AUTOSAR XML (schema 4-1-3)
standard types defined: boolean, sint8, uint16, uint32, uint8, boolean_CompuMethod, boolean_DataConstr, sint8_DataConstr, uint16_DataConstr, uint32_DataConstr, uint8_DataConstr, sint16
package /MICROSAR/Dem_swc/DataTypes
  5 x impl type:
    Dem_DebounceResetStatusType: compu {0=DEM_DEBOUNCE_STATUS_FREEZE, 1=DEM_DEBOUNCE_STATUS_RESET}, range raw 0..255, implementation-data-type=ImplementationDataTypes/uint8
    Dem_DTCFormatType: compu {0=DEM_DTC_FORMAT_OBD, 1=DEM_DTC_FORMAT_UDS, 2=DEM_DTC_FORMAT_J1939}, range raw 0..2, implementation-data-type=ImplementationDataTypes/uint8
    Dem_EventStatusType:
      compu {0=DEM_EVENT_STATUS_PASSED, 1=DEM_EVENT_STATUS_FAILED, 2=DEM_EVENT_STATUS_PREPASSED, 3=DEM_EVENT_STATUS_PREFAILED, 4=DEM_EVENT_STATUS_FDC_THRESHOLD_REACHED, 5=DEM_EVENT_STATUS_PASSED_CONDITIONS_NOT_FULFILLED, 6=DEM_EVENT_STATUS_FAILED_CONDITIONS_NOT_FULFILLED, 7=DEM_EVENT_STATUS_PREPASSED_CONDITIONS_NOT_FULFILLED, 8=DEM_EVENT_STATUS_PREFAILED_CONDITIONS_NOT_FULFILLED}
      range raw 0..255
      implementation-data-type=ImplementationDataTypes/uint8
    Dem_MaxDataValueType: category=ARRAY, sw-calibration-access=READ-ONLY
      element Dem_MaxDataValueTypeElement: array-size=14, array-size-semantics=FIXED-SIZE, implementation-data-type=ImplementationDataTypes/uint8
    Dem_UdsStatusByteType:
      compu {mask 1: 1=DEM_UDS_STATUS_TF (bit 0: TestFailed), mask 2: 2=DEM_UDS_STATUS_TFTOC (bit 1: TestFailedThisOperationCycle), mask 4: 4=DEM_UDS_STATUS_PDTC (bit 2: PendingDTC), mask 8: 8=DEM_UDS_STATUS_CDTC (bit 3: ConfirmedDTC), mask 16: 16=DEM_UDS_STATUS_TNCSLC (bit 4: TestNotCompletedSinceLastClear), mask 32: 32=DEM_UDS_STATUS_TFSLC (bit 5: TestFailedSinceLastClear), mask 64: 64=DEM_UDS_STATUS_TNCTOC (bit 6: TestNotCompletedThisOperationCycle), mask 128: 128=DEM_UDS_STATUS_WIR (bit 7: WarningIndicatorRequested)}
      range raw 0..255
      implementation-data-type=ImplementationDataTypes/uint8
package /MICROSAR/Dem_swc/Interfaces
  client server interface DiagnosticMonitor: is-service=true, service-kind=DIAGNOSTIC-EVENT-MANAGER
    11 x operation:
      GetDTCOfEvent: possible-error=[DEM_E_NO_DTC_AVAILABLE, E_NOT_OK]
        arg DTCFormat: type=Dem_DTCFormatType, direction=IN, server-argument-impl-policy=USE-ARGUMENT-TYPE
        arg DTCOfEvent: type=ImplementationDataTypes/uint32, direction=OUT, server-argument-impl-policy=USE-ARGUMENT-TYPE
      GetEventExtendedDataRecordEx: possible-error=[DEM_BUFFER_TOO_SMALL, DEM_NO_SUCH_ELEMENT, E_NOT_OK]
        arg RecordNumber: type=ImplementationDataTypes/uint8, direction=IN, server-argument-impl-policy=USE-ARGUMENT-TYPE
        arg DestBuffer: type=Dem_MaxDataValueType, direction=OUT, server-argument-impl-policy=USE-ARGUMENT-TYPE
        arg BufSize: type=ImplementationDataTypes/uint16, direction=INOUT, server-argument-impl-policy=USE-ARGUMENT-TYPE
      GetEventFailed: possible-error=E_NOT_OK
        arg EventFailed: type=ImplementationDataTypes/boolean, direction=OUT, server-argument-impl-policy=USE-ARGUMENT-TYPE
      GetEventFreezeFrameDataEx: possible-error=[DEM_BUFFER_TOO_SMALL, DEM_NO_SUCH_ELEMENT, E_NOT_OK]
        4 x arg, all with server-argument-impl-policy=USE-ARGUMENT-TYPE:
          RecordNumber: type=ImplementationDataTypes/uint8, direction=IN
          DataId: type=ImplementationDataTypes/uint16, direction=IN
          DestBuffer: type=Dem_MaxDataValueType, direction=OUT
          BufSize: type=ImplementationDataTypes/uint16, direction=INOUT
      GetEventStatus: possible-error=E_NOT_OK
        arg UDSStatusByte: type=Dem_UdsStatusByteType, direction=OUT, server-argument-impl-policy=USE-ARGUMENT-TYPE
      GetEventTested: possible-error=E_NOT_OK
        arg EventTested: type=ImplementationDataTypes/boolean, direction=OUT, server-argument-impl-policy=USE-ARGUMENT-TYPE
      GetEventUdsStatus: possible-error=E_NOT_OK
        arg UDSStatusByte: type=Dem_UdsStatusByteType, direction=OUT, server-argument-impl-policy=USE-ARGUMENT-TYPE
      GetFaultDetectionCounter: possible-error=[DEM_E_NO_FDC_AVAILABLE, E_NOT_OK]
        arg FaultDetectionCounter: type=sint8, direction=OUT, server-argument-impl-policy=USE-ARGUMENT-TYPE
      ResetEventDebounceStatus: possible-error=E_NOT_OK
        arg DebounceResetStatus: type=Dem_DebounceResetStatusType, direction=IN, server-argument-impl-policy=USE-ARGUMENT-TYPE
      ResetEventStatus: possible-error=E_NOT_OK
      SetEventStatus: possible-error=E_NOT_OK
        arg EventStatus: type=Dem_EventStatusType, direction=IN, server-argument-impl-policy=USE-ARGUMENT-TYPE
    5 x error:
      DEM_BUFFER_TOO_SMALL: error-code=21
      DEM_E_NO_DTC_AVAILABLE: error-code=10
      DEM_E_NO_FDC_AVAILABLE: error-code=14
      DEM_NO_SUCH_ELEMENT: error-code=48
      E_NOT_OK: error-code=1
package /RB/ApplicationSW/PT/CompuMethods
  compu method CM_boolean: 0=FALSE, 1=TRUE
package /RB/ApplicationSW/PT/Units
  unit NoUnit: factor-si-to-unit=1, offset-si-to-unit=0
package /UAES/ASW/ApplicationDataType
  application array data type Array_Curr_q0p01_A_s16_10: category=ARRAY, sw-calibration-access=READ-WRITE
    element Array_Curr_q0p01_A_s16_10: category=VALUE, type=ApplicationDataType/Curr_q0p01_A_s16, array-size-semantics=FIXED-SIZE, max-number-of-elements=10
  app type Curr_q0p01_A_s16: category=VALUE, sw-calibration-access=READ-WRITE, compu {phys=raw*0.01 for raw -INF..INF; unit A}, range raw -32768..32767
package /UAES/ASW/ApplicationDataTypes
  application array data type Array_Curr_q0p01_A_s16_10: category=ARRAY, sw-calibration-access=READ-WRITE
    element Array_Curr_q0p01_A_s16_10: category=VALUE, type=ApplicationDataTypes/Curr_q0p01_A_s16, array-size-semantics=FIXED-SIZE, max-number-of-elements=10
  4 x app type, all with category=VALUE, sw-calibration-access=READ-WRITE:
    Curr_q0p01_A_s16: compu {phys=raw*0.01 for raw -INF..INF; unit A}, range phys -327.68..-327.67
    Curr_q0p136_A_s16: compu {phys=raw*0.136 for raw -INF..INF; unit A}, range phys -100..100
    T_q1_o63_DegC_s16: compu {phys=raw-63 for raw -INF..INF; unit ℃}, range phys -63..650
    Tq_q0p001_kN_u16: compu {phys=raw*0.001 for raw -INF..INF; unit kN}, range phys 0..50
package /UAES/ASW/DataConstrs
  range DC_boolean: raw 0..1
  range DC_sint16: raw -32768..32767
  range DC_uint16: raw 0..65535
  range DC_uint32: raw 0..4294967295
  range DC_uint8: raw 0..255
package /UAES/ASW/DataTypeMappingSets
  data type mapping set DTMS_EPB_SysSrvAdpCust
    data-type-maps:
      application-data-type=ApplicationDataType/Array_Curr_q0p01_A_s16_10, implementation-data-type=Array_sint16_10
      application-data-type=ApplicationDataType/Curr_q0p01_A_s16, implementation-data-type=sint16
      application-data-type=ApplicationDataTypes/Array_Curr_q0p01_A_s16_10, implementation-data-type=Array_sint16_10
      application-data-type=ApplicationDataTypes/Curr_q0p01_A_s16, implementation-data-type=sint16
      application-data-type=Curr_q0p136_A_s16, implementation-data-type=sint16
      application-data-type=T_q1_o63_DegC_s16, implementation-data-type=sint16
      application-data-type=Tq_q0p001_kN_u16, implementation-data-type=ImplementationDataTypes/uint16
package /UAES/ASW/ImplementationDataTypes
  6 x impl type, all with category=ARRAY, sw-calibration-access=READ-ONLY, type-emitter=RTE:
    Array_sint16_10
      element Array_sint16_10: array-size=10, array-size-semantics=FIXED-SIZE, implementation-data-type=sint16
    Array_uint8_128
      element Array_uint8_128: array-size=128, array-size-semantics=FIXED-SIZE, implementation-data-type=ImplementationDataTypes/uint8
    Array_uint8_30
      element Array_uint8_30: array-size=30, array-size-semantics=FIXED-SIZE, implementation-data-type=ImplementationDataTypes/uint8
    Array_uint8_4
      element Array_uint8_4: array-size=4, array-size-semantics=FIXED-SIZE, implementation-data-type=ImplementationDataTypes/uint8
    Array_uint8_40
      element Array_uint8_40: array-size=40, array-size-semantics=FIXED-SIZE, implementation-data-type=ImplementationDataTypes/uint8
    Array_uint8_6
      element Array_uint8_6: array-size=6, array-size-semantics=FIXED-SIZE, implementation-data-type=ImplementationDataTypes/uint8
package /UAES/ASW/PortInterfaces
  43 x sender receiver interface:
    EPB_bFunctionFailed: invalidation-policy{data-element=EPB_bFunctionFailed/Val, handle-invalid=DONT-INVALIDATE}
      data Val: sw-calibration-access=READ-ONLY, type=ImplementationDataTypes/boolean
    EPB_cntPbcOutDiagActuationCounter: invalidation-policy{data-element=EPB_cntPbcOutDiagActuationCounter/Val, handle-invalid=DONT-INVALIDATE}
      data Val: sw-calibration-access=READ-ONLY, type=ImplementationDataTypes/uint32
    EPB_PbcInHostSwVersion: invalidation-policy{data-element=EPB_PbcInHostSwVersion/Val, handle-invalid=DONT-INVALIDATE}
      data Val: sw-calibration-access=READ-ONLY, type=Array_uint8_6
    EPB_PbcOutPbcSoftwareVersion: invalidation-policy{data-element=EPB_PbcOutPbcSoftwareVersion/Val, handle-invalid=DONT-INVALIDATE}
      data Val: sw-calibration-access=READ-ONLY, type=Array_uint8_6
    EPB_SSMInDataStorageRead: invalidation-policy{data-element=EPB_SSMInDataStorageRead/Val, handle-invalid=DONT-INVALIDATE}
      data Val: sw-calibration-access=READ-WRITE, type=Array_uint8_128
    EPB_SSMOutDataStorageWrite: invalidation-policy{data-element=EPB_SSMOutDataStorageWrite/Val, handle-invalid=DONT-INVALIDATE}
      data Val: sw-calibration-access=READ-WRITE, type=Array_uint8_128
    EPB_stButtonInFaultMonitorStatusReset: invalidation-policy{data-element=EPB_stButtonInFaultMonitorStatusReset/Val, handle-invalid=DONT-INVALIDATE}
      data Val: sw-calibration-access=READ-WRITE, type=ImplementationDataTypes/uint8
    EPB_stButtonOutFaultMonitorStatus: invalidation-policy{data-element=EPB_stButtonOutFaultMonitorStatus/Val, handle-invalid=DONT-INVALIDATE}
      data Val: sw-calibration-access=READ-WRITE, type=ImplementationDataTypes/uint8
    EPB_stPbcOutDiagActuatorState: invalidation-policy{data-element=EPB_stPbcOutDiagActuatorState/Val, handle-invalid=DONT-INVALIDATE}
      data Val: sw-calibration-access=READ-ONLY, type=ImplementationDataTypes/uint8
    EPB_stPbcOutEcuPowerLatchRequest: invalidation-policy{data-element=EPB_stPbcOutEcuPowerLatchRequest/Val, handle-invalid=DONT-INVALIDATE}
      data Val: sw-calibration-access=READ-ONLY, type=ImplementationDataTypes/uint8
    EPB_stPbcOutFaultStatus: invalidation-policy{data-element=EPB_stPbcOutFaultStatus/Val, handle-invalid=DONT-INVALIDATE}
      data Val: sw-calibration-access=READ-WRITE, type=Array_uint8_40
    EPB_stSSMInDataStorageValid: invalidation-policy{data-element=EPB_stSSMInDataStorageValid/Val, handle-invalid=DONT-INVALIDATE}
      data Val: sw-calibration-access=READ-WRITE, type=ImplementationDataTypes/uint8
    EPB_stSsmInFunctionConfig: invalidation-policy{data-element=EPB_stSsmInFunctionConfig/Val, handle-invalid=DONT-INVALIDATE}
      data Val: sw-calibration-access=READ-ONLY, type=ImplementationDataTypes/uint8
    EPB_stSsmInVariantCode: invalidation-policy{data-element=EPB_stSsmInVariantCode/Val, handle-invalid=DONT-INVALIDATE}
      data Val: sw-calibration-access=READ-ONLY, type=Array_uint8_4
    EPB_stSsmInVehicleTypeCfg: invalidation-policy{data-element=EPB_stSsmInVehicleTypeCfg/Val, handle-invalid=DONT-INVALIDATE}
      data Val: sw-calibration-access=READ-ONLY, type=ImplementationDataTypes/uint8
    EPB_stSsmOutCommunicationLatchRequest: invalidation-policy{data-element=EPB_stSsmOutCommunicationLatchRequest/Val, handle-invalid=DONT-INVALIDATE}
      data Val: sw-calibration-access=READ-ONLY, type=ImplementationDataTypes/uint8
    EPB_stSsmOutEpbSwtCycle: invalidation-policy{data-element=EPB_stSsmOutEpbSwtCycle/Val, handle-invalid=DONT-INVALIDATE}
      data Val: sw-calibration-access=READ-ONLY, type=ImplementationDataTypes/uint8
    EPB_stSsmOutFaultStatus: invalidation-policy{data-element=EPB_stSsmOutFaultStatus/Val, handle-invalid=DONT-INVALIDATE}
      data Val: sw-calibration-access=READ-ONLY, type=Array_uint8_30
    EPB_stSsmOutPrkBrkAplSwt: invalidation-policy{data-element=EPB_stSsmOutPrkBrkAplSwt/Val, handle-invalid=DONT-INVALIDATE}
      data Val: sw-calibration-access=READ-ONLY, type=ImplementationDataTypes/uint8
    EPB_stSsmOutSysState: invalidation-policy{data-element=EPB_stSsmOutSysState/Val, handle-invalid=DONT-INVALIDATE}
      data Val: sw-calibration-access=READ-ONLY, type=ImplementationDataTypes/uint8
    EPB_tPbcOutDiagBrakeTemperature: invalidation-policy{data-element=EPB_tPbcOutDiagBrakeTemperature/Val, handle-invalid=DONT-INVALIDATE}
      data Val: sw-calibration-access=READ-ONLY, type=sint16
    EPB_tqPbcOutDiagAchievedClampForce: invalidation-policy{data-element=EPB_tqPbcOutDiagAchievedClampForce/Val, handle-invalid=DONT-INVALIDATE}
      data Val: sw-calibration-access=READ-ONLY, type=ImplementationDataTypes/uint16
    EPBCalprDrvr_CurrMotDrvrCurr_a: invalidation-policy{data-element=EPBCalprDrvr_CurrMotDrvrCurr_a/Val, handle-invalid=DONT-INVALIDATE}
      data Val: sw-calibration-access=READ-ONLY, type=ApplicationDataType/Array_Curr_q0p01_A_s16_10
    gCFG_u8SsmInFunctionConfig: invalidation-policy{data-element=gCFG_u8SsmInFunctionConfig/Val, handle-invalid=DONT-INVALIDATE}
      data Val: sw-calibration-access=READ-ONLY, type=ImplementationDataTypes/uint8
    gCFG_u8SsmInVariantCoding: invalidation-policy{data-element=gCFG_u8SsmInVariantCoding/Val, handle-invalid=DONT-INVALIDATE}
      data Val: sw-calibration-access=READ-ONLY, type=Array_uint8_4
    gDiag_bDSMClear: invalidation-policy{data-element=gDiag_bDSMClear/Val, handle-invalid=DONT-INVALIDATE}
      data Val: sw-calibration-access=READ-ONLY, type=ImplementationDataTypes/boolean
    gEPB_s16PbcOutCurrMotDrvrCurr: invalidation-policy{data-element=gEPB_s16PbcOutCurrMotDrvrCurr/Val, handle-invalid=DONT-INVALIDATE}
      data Val: sw-calibration-access=READ-ONLY, type=Curr_q0p136_A_s16
    gEPB_s16PbcOutDiagBrakeTemperature: invalidation-policy{data-element=gEPB_s16PbcOutDiagBrakeTemperature/Val, handle-invalid=DONT-INVALIDATE}
      data Val: sw-calibration-access=READ-ONLY, type=T_q1_o63_DegC_s16
    gEPB_u16PbcOutDiagAchievedClampForce: invalidation-policy{data-element=gEPB_u16PbcOutDiagAchievedClampForce/Val, handle-invalid=DONT-INVALIDATE}
      data Val: sw-calibration-access=READ-ONLY, type=Tq_q0p001_kN_u16
    gEPB_u32AllowSleep_Local: invalidation-policy{data-element=gEPB_u32AllowSleep_Local/Val, handle-invalid=DONT-INVALIDATE}
      data Val: sw-calibration-access=READ-ONLY, type=ImplementationDataTypes/uint32
    gEPB_u32AllowSleep_NW: invalidation-policy{data-element=gEPB_u32AllowSleep_NW/Val, handle-invalid=DONT-INVALIDATE}
      data Val: sw-calibration-access=READ-ONLY, type=ImplementationDataTypes/uint32
    gEPB_u32PbcOutDiagActuationCounter: invalidation-policy{data-element=gEPB_u32PbcOutDiagActuationCounter/Val, handle-invalid=DONT-INVALIDATE}
      data Val: sw-calibration-access=READ-ONLY, type=ImplementationDataTypes/uint32
    gEPB_u8HostSoftwareVersion: invalidation-policy{data-element=gEPB_u8HostSoftwareVersion/Val, handle-invalid=DONT-INVALIDATE}
      data Val: sw-calibration-access=READ-ONLY, type=Array_uint8_6
    gEPB_u8PbcOutDiagActuatorState: invalidation-policy{data-element=gEPB_u8PbcOutDiagActuatorState/Val, handle-invalid=DONT-INVALIDATE}
      data Val: sw-calibration-access=READ-ONLY, type=ImplementationDataTypes/uint8
    gEPB_u8PbcOutPbcSoftwareVersion: invalidation-policy{data-element=gEPB_u8PbcOutPbcSoftwareVersion/Val, handle-invalid=DONT-INVALIDATE}
      data Val: sw-calibration-access=READ-ONLY, type=Array_uint8_6
    gEPB_u8SsmoutDataStorageWrite_a: invalidation-policy{data-element=gEPB_u8SsmoutDataStorageWrite_a/Val, handle-invalid=DONT-INVALIDATE}
      data Val: sw-calibration-access=READ-ONLY, type=Array_uint8_128
    gEPB_u8SsmoutDataStorageWrtCnt: invalidation-policy{data-element=gEPB_u8SsmoutDataStorageWrtCnt/Val, handle-invalid=DONT-INVALIDATE}
      data Val: sw-calibration-access=READ-ONLY, type=ImplementationDataTypes/uint8
    gEPB_u8SsmOutEpbSwtCycle: invalidation-policy{data-element=gEPB_u8SsmOutEpbSwtCycle/Val, handle-invalid=DONT-INVALIDATE}
      data Val: sw-calibration-access=READ-ONLY, type=ImplementationDataTypes/uint8
    gEPB_u8SsmOutPrkBrkAplSwt: invalidation-policy{data-element=gEPB_u8SsmOutPrkBrkAplSwt/Val, handle-invalid=DONT-INVALIDATE}
      data Val: sw-calibration-access=READ-ONLY, type=ImplementationDataTypes/uint8
    gEPB_u8SsmOutSysState: invalidation-policy{data-element=gEPB_u8SsmOutSysState/Val, handle-invalid=DONT-INVALIDATE}
      data Val: sw-calibration-access=READ-ONLY, type=ImplementationDataTypes/uint8
    gEPB_u8Wakeup: invalidation-policy{data-element=gEPB_u8Wakeup/Val, handle-invalid=DONT-INVALIDATE}
      data Val: sw-calibration-access=READ-ONLY, type=ImplementationDataTypes/uint8
    gNVM_bSsminDataStorageValid: invalidation-policy{data-element=gNVM_bSsminDataStorageValid/Val, handle-invalid=DONT-INVALIDATE}
      data Val: sw-calibration-access=READ-ONLY, type=ImplementationDataTypes/boolean
    gNVM_u8SsminDataStorageRead_a: invalidation-policy{data-element=gNVM_u8SsminDataStorageRead_a/Val, handle-invalid=DONT-INVALIDATE}
      data Val: sw-calibration-access=READ-ONLY, type=Array_uint8_128
package /UAES/ASW/SwComponentTypes
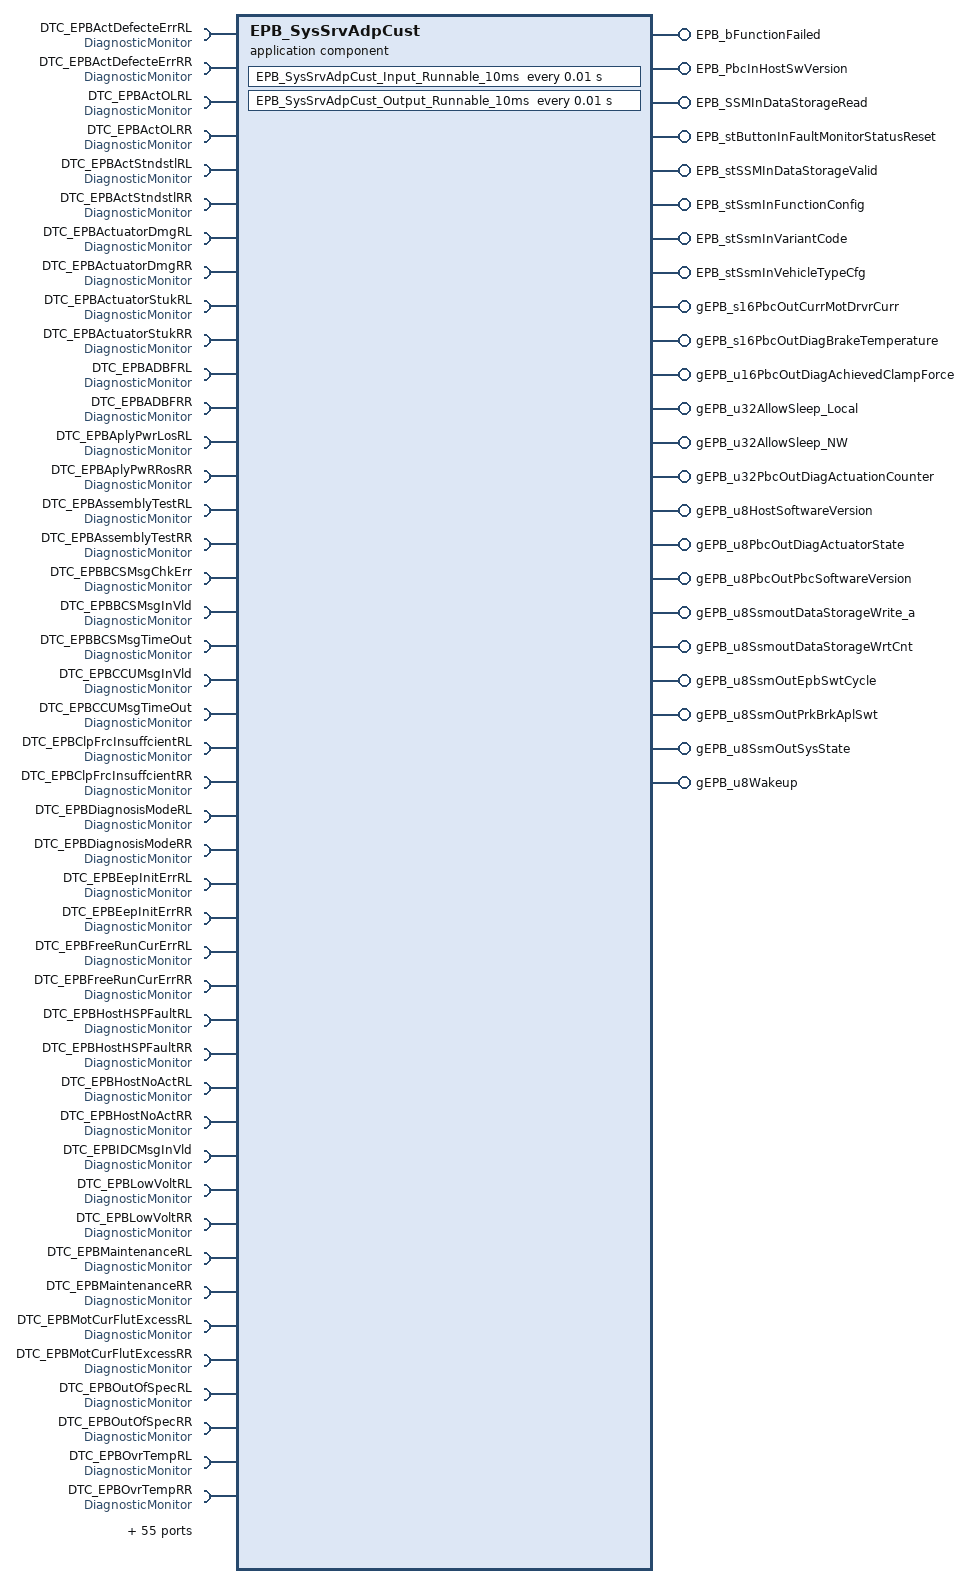
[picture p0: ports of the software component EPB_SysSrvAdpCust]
  application sw component type EPB_SysSrvAdpCust
    23 x provide port:
      EPB_bFunctionFailed: nonqueued-sender-com-spec{data-element=EPB_bFunctionFailed/Val, init-value=0}, provided-interface=EPB_bFunctionFailed
      EPB_PbcInHostSwVersion: nonqueued-sender-com-spec{data-element=EPB_PbcInHostSwVersion/Val, init-value=6 x 0}, provided-interface=EPB_PbcInHostSwVersion
      EPB_SSMInDataStorageRead: nonqueued-sender-com-spec{data-element=EPB_SSMInDataStorageRead/Val, init-value=128 x 0}, provided-interface=EPB_SSMInDataStorageRead
      EPB_stButtonInFaultMonitorStatusReset: nonqueued-sender-com-spec{data-element=EPB_stButtonInFaultMonitorStatusReset/Val, init-value=0}, provided-interface=EPB_stButtonInFaultMonitorStatusReset
      EPB_stSSMInDataStorageValid: nonqueued-sender-com-spec{data-element=EPB_stSSMInDataStorageValid/Val, init-value=0}, provided-interface=EPB_stSSMInDataStorageValid
      EPB_stSsmInFunctionConfig: nonqueued-sender-com-spec{data-element=EPB_stSsmInFunctionConfig/Val, init-value=0}, provided-interface=EPB_stSsmInFunctionConfig
      EPB_stSsmInVariantCode: nonqueued-sender-com-spec{data-element=EPB_stSsmInVariantCode/Val, init-value=[0, 0, 0, 0]}, provided-interface=EPB_stSsmInVariantCode
      EPB_stSsmInVehicleTypeCfg: nonqueued-sender-com-spec{data-element=EPB_stSsmInVehicleTypeCfg/Val, init-value=0}, provided-interface=EPB_stSsmInVehicleTypeCfg
      gEPB_s16PbcOutCurrMotDrvrCurr: nonqueued-sender-com-spec{data-element=gEPB_s16PbcOutCurrMotDrvrCurr/Val, init-value=0}, provided-interface=gEPB_s16PbcOutCurrMotDrvrCurr
      gEPB_s16PbcOutDiagBrakeTemperature: nonqueued-sender-com-spec{data-element=gEPB_s16PbcOutDiagBrakeTemperature/Val, init-value=0}, provided-interface=gEPB_s16PbcOutDiagBrakeTemperature
      gEPB_u16PbcOutDiagAchievedClampForce: nonqueued-sender-com-spec{data-element=gEPB_u16PbcOutDiagAchievedClampForce/Val, init-value=0}, provided-interface=gEPB_u16PbcOutDiagAchievedClampForce
      gEPB_u32AllowSleep_Local: nonqueued-sender-com-spec=data-element=gEPB_u32AllowSleep_Local/Val, provided-interface=gEPB_u32AllowSleep_Local
      gEPB_u32AllowSleep_NW: nonqueued-sender-com-spec=data-element=gEPB_u32AllowSleep_NW/Val, provided-interface=gEPB_u32AllowSleep_NW
      gEPB_u32PbcOutDiagActuationCounter: nonqueued-sender-com-spec{data-element=gEPB_u32PbcOutDiagActuationCounter/Val, init-value=0}, provided-interface=gEPB_u32PbcOutDiagActuationCounter
      gEPB_u8HostSoftwareVersion: nonqueued-sender-com-spec{data-element=gEPB_u8HostSoftwareVersion/Val, init-value=6 x 0}, provided-interface=gEPB_u8HostSoftwareVersion
      gEPB_u8PbcOutDiagActuatorState: nonqueued-sender-com-spec{data-element=gEPB_u8PbcOutDiagActuatorState/Val, init-value=0}, provided-interface=gEPB_u8PbcOutDiagActuatorState
      gEPB_u8PbcOutPbcSoftwareVersion: nonqueued-sender-com-spec{data-element=gEPB_u8PbcOutPbcSoftwareVersion/Val, init-value=6 x 0}, provided-interface=gEPB_u8PbcOutPbcSoftwareVersion
      gEPB_u8SsmoutDataStorageWrite_a: nonqueued-sender-com-spec{data-element=gEPB_u8SsmoutDataStorageWrite_a/Val, init-value=128 x 0}, provided-interface=gEPB_u8SsmoutDataStorageWrite_a
      gEPB_u8SsmoutDataStorageWrtCnt: nonqueued-sender-com-spec{data-element=gEPB_u8SsmoutDataStorageWrtCnt/Val, init-value=0}, provided-interface=gEPB_u8SsmoutDataStorageWrtCnt
      gEPB_u8SsmOutEpbSwtCycle: nonqueued-sender-com-spec{data-element=gEPB_u8SsmOutEpbSwtCycle/Val, init-value=0}, provided-interface=gEPB_u8SsmOutEpbSwtCycle
      gEPB_u8SsmOutPrkBrkAplSwt: nonqueued-sender-com-spec{data-element=gEPB_u8SsmOutPrkBrkAplSwt/Val, init-value=0}, provided-interface=gEPB_u8SsmOutPrkBrkAplSwt
      gEPB_u8SsmOutSysState: nonqueued-sender-com-spec{data-element=gEPB_u8SsmOutSysState/Val, init-value=0}, provided-interface=gEPB_u8SsmOutSysState
      gEPB_u8Wakeup: nonqueued-sender-com-spec=data-element=gEPB_u8Wakeup/Val, provided-interface=gEPB_u8Wakeup
    99 x require port:
      DTC_EPBActDefecteErrRL: required-interface=DiagnosticMonitor
        required-com-specs:
          GetDTCOfEvent
          GetEventExtendedDataRecordEx
          GetEventFailed
          GetEventFreezeFrameDataEx
          GetEventStatus
          GetEventTested
          GetEventUdsStatus
          GetFaultDetectionCounter
          ResetEventDebounceStatus
          ResetEventStatus
          SetEventStatus
      DTC_EPBActDefecteErrRR: required-interface=DiagnosticMonitor
        required-com-specs:
          GetDTCOfEvent
          GetEventExtendedDataRecordEx
          GetEventFailed
          GetEventFreezeFrameDataEx
          GetEventStatus
          GetEventTested
          GetEventUdsStatus
          GetFaultDetectionCounter
          ResetEventDebounceStatus
          ResetEventStatus
          SetEventStatus
      DTC_EPBActOLRL: required-interface=DiagnosticMonitor
        required-com-specs:
          GetDTCOfEvent
          GetEventExtendedDataRecordEx
          GetEventFailed
          GetEventFreezeFrameDataEx
          GetEventStatus
          GetEventTested
          GetEventUdsStatus
          GetFaultDetectionCounter
          ResetEventDebounceStatus
          ResetEventStatus
          SetEventStatus
      DTC_EPBActOLRR: required-interface=DiagnosticMonitor
        required-com-specs:
          GetDTCOfEvent
          GetEventExtendedDataRecordEx
          GetEventFailed
          GetEventFreezeFrameDataEx
          GetEventStatus
          GetEventTested
          GetEventUdsStatus
          GetFaultDetectionCounter
          ResetEventDebounceStatus
          ResetEventStatus
          SetEventStatus
      DTC_EPBActStndstlRL: required-interface=DiagnosticMonitor
        required-com-specs:
          GetDTCOfEvent
          GetEventExtendedDataRecordEx
          GetEventFailed
          GetEventFreezeFrameDataEx
          GetEventStatus
          GetEventTested
          GetEventUdsStatus
          GetFaultDetectionCounter
          ResetEventDebounceStatus
          ResetEventStatus
          SetEventStatus
      DTC_EPBActStndstlRR: required-interface=DiagnosticMonitor
        required-com-specs:
          GetDTCOfEvent
          GetEventExtendedDataRecordEx
          GetEventFailed
          GetEventFreezeFrameDataEx
          GetEventStatus
          GetEventTested
          GetEventUdsStatus
          GetFaultDetectionCounter
          ResetEventDebounceStatus
          ResetEventStatus
          SetEventStatus
      DTC_EPBActuatorDmgRL: required-interface=DiagnosticMonitor
        required-com-specs:
          GetDTCOfEvent
          GetEventExtendedDataRecordEx
          GetEventFailed
          GetEventFreezeFrameDataEx
          GetEventStatus
          GetEventTested
          GetEventUdsStatus
          GetFaultDetectionCounter
          ResetEventDebounceStatus
          ResetEventStatus
          SetEventStatus
      DTC_EPBActuatorDmgRR: required-interface=DiagnosticMonitor
        required-com-specs:
          GetDTCOfEvent
          GetEventExtendedDataRecordEx
          GetEventFailed
          GetEventFreezeFrameDataEx
          GetEventStatus
          GetEventTested
          GetEventUdsStatus
          GetFaultDetectionCounter
          ResetEventDebounceStatus
          ResetEventStatus
          SetEventStatus
      DTC_EPBActuatorStukRL: required-interface=DiagnosticMonitor
        required-com-specs:
          GetDTCOfEvent
          GetEventExtendedDataRecordEx
          GetEventFailed
          GetEventFreezeFrameDataEx
          GetEventStatus
          GetEventTested
          GetEventUdsStatus
          GetFaultDetectionCounter
          ResetEventDebounceStatus
          ResetEventStatus
          SetEventStatus
      DTC_EPBActuatorStukRR: required-interface=DiagnosticMonitor
        required-com-specs:
          GetDTCOfEvent
          GetEventExtendedDataRecordEx
          GetEventFailed
          GetEventFreezeFrameDataEx
          GetEventStatus
          GetEventTested
          GetEventUdsStatus
          GetFaultDetectionCounter
          ResetEventDebounceStatus
          ResetEventStatus
          SetEventStatus
      DTC_EPBADBFRL: required-interface=DiagnosticMonitor
        required-com-specs:
          GetDTCOfEvent
          GetEventExtendedDataRecordEx
          GetEventFailed
          GetEventFreezeFrameDataEx
          GetEventStatus
          GetEventTested
          GetEventUdsStatus
          GetFaultDetectionCounter
          ResetEventDebounceStatus
          ResetEventStatus
          SetEventStatus
      DTC_EPBADBFRR: required-interface=DiagnosticMonitor
        required-com-specs:
          GetDTCOfEvent
          GetEventExtendedDataRecordEx
          GetEventFailed
          GetEventFreezeFrameDataEx
          GetEventStatus
          GetEventTested
          GetEventUdsStatus
          GetFaultDetectionCounter
          ResetEventDebounceStatus
          ResetEventStatus
          SetEventStatus
      DTC_EPBAplyPwrLosRL: required-interface=DiagnosticMonitor
        required-com-specs:
          GetDTCOfEvent
          GetEventExtendedDataRecordEx
          GetEventFailed
          GetEventFreezeFrameDataEx
          GetEventStatus
          GetEventTested
          GetEventUdsStatus
          GetFaultDetectionCounter
          ResetEventDebounceStatus
          ResetEventStatus
          SetEventStatus
      DTC_EPBAplyPwRRosRR: required-interface=DiagnosticMonitor
        required-com-specs:
          GetDTCOfEvent
          GetEventExtendedDataRecordEx
          GetEventFailed
          GetEventFreezeFrameDataEx
          GetEventStatus
          GetEventTested
          GetEventUdsStatus
          GetFaultDetectionCounter
          ResetEventDebounceStatus
          ResetEventStatus
          SetEventStatus
      DTC_EPBAssemblyTestRL: required-interface=DiagnosticMonitor
        required-com-specs:
          GetDTCOfEvent
          GetEventExtendedDataRecordEx
          GetEventFailed
          GetEventFreezeFrameDataEx
          GetEventStatus
          GetEventTested
          GetEventUdsStatus
          GetFaultDetectionCounter
          ResetEventDebounceStatus
          ResetEventStatus
          SetEventStatus
      DTC_EPBAssemblyTestRR: required-interface=DiagnosticMonitor
        required-com-specs:
          GetDTCOfEvent
          GetEventExtendedDataRecordEx
          GetEventFailed
          GetEventFreezeFrameDataEx
          GetEventStatus
          GetEventTested
          GetEventUdsStatus
          GetFaultDetectionCounter
          ResetEventDebounceStatus
          ResetEventStatus
          SetEventStatus
      DTC_EPBBCSMsgChkErr: required-interface=DiagnosticMonitor
        required-com-specs:
          GetDTCOfEvent
          GetEventExtendedDataRecordEx
          GetEventFailed
          GetEventFreezeFrameDataEx
          GetEventStatus
          GetEventTested
          GetEventUdsStatus
          GetFaultDetectionCounter
          ResetEventDebounceStatus
          ResetEventStatus
          SetEventStatus
      DTC_EPBBCSMsgInVld: required-interface=DiagnosticMonitor
        required-com-specs:
          GetDTCOfEvent
          GetEventExtendedDataRecordEx
          GetEventFailed
          GetEventFreezeFrameDataEx
          GetEventStatus
          GetEventTested
          GetEventUdsStatus
          GetFaultDetectionCounter
          ResetEventDebounceStatus
          ResetEventStatus
          SetEventStatus
      DTC_EPBBCSMsgTimeOut: required-interface=DiagnosticMonitor
        required-com-specs:
          GetDTCOfEvent
          GetEventExtendedDataRecordEx
          GetEventFailed
          GetEventFreezeFrameDataEx
          GetEventStatus
          GetEventTested
          GetEventUdsStatus
          GetFaultDetectionCounter
          ResetEventDebounceStatus
          ResetEventStatus
          SetEventStatus
      DTC_EPBCCUMsgInVld: required-interface=DiagnosticMonitor
        required-com-specs:
          GetDTCOfEvent
          GetEventExtendedDataRecordEx
          GetEventFailed
          GetEventFreezeFrameDataEx
          GetEventStatus
          GetEventTested
          GetEventUdsStatus
          GetFaultDetectionCounter
          ResetEventDebounceStatus
          ResetEventStatus
          SetEventStatus
      DTC_EPBCCUMsgTimeOut: required-interface=DiagnosticMonitor
        required-com-specs:
          GetDTCOfEvent
          GetEventExtendedDataRecordEx
          GetEventFailed
          GetEventFreezeFrameDataEx
          GetEventStatus
          GetEventTested
          GetEventUdsStatus
          GetFaultDetectionCounter
          ResetEventDebounceStatus
          ResetEventStatus
          SetEventStatus
      DTC_EPBClpFrcInsuffcientRL: required-interface=DiagnosticMonitor
        required-com-specs:
          GetDTCOfEvent
          GetEventExtendedDataRecordEx
          GetEventFailed
          GetEventFreezeFrameDataEx
          GetEventStatus
          GetEventTested
          GetEventUdsStatus
          GetFaultDetectionCounter
          ResetEventDebounceStatus
          ResetEventStatus
          SetEventStatus
      DTC_EPBClpFrcInsuffcientRR: required-interface=DiagnosticMonitor
        required-com-specs:
          GetDTCOfEvent
          GetEventExtendedDataRecordEx
          GetEventFailed
          GetEventFreezeFrameDataEx
          GetEventStatus
          GetEventTested
          GetEventUdsStatus
          GetFaultDetectionCounter
          ResetEventDebounceStatus
          ResetEventStatus
          SetEventStatus
      DTC_EPBDiagnosisModeRL: required-interface=DiagnosticMonitor
        required-com-specs:
          GetDTCOfEvent
          GetEventExtendedDataRecordEx
          GetEventFailed
          GetEventFreezeFrameDataEx
          GetEventStatus
          GetEventTested
          GetEventUdsStatus
          GetFaultDetectionCounter
          ResetEventDebounceStatus
          ResetEventStatus
          SetEventStatus
      DTC_EPBDiagnosisModeRR: required-interface=DiagnosticMonitor
        required-com-specs:
          GetDTCOfEvent
          GetEventExtendedDataRecordEx
          GetEventFailed
          GetEventFreezeFrameDataEx
          GetEventStatus
          GetEventTested
          GetEventUdsStatus
          GetFaultDetectionCounter
          ResetEventDebounceStatus
          ResetEventStatus
          SetEventStatus
      DTC_EPBEepInitErrRL: required-interface=DiagnosticMonitor
        required-com-specs:
          GetDTCOfEvent
          GetEventExtendedDataRecordEx
          GetEventFailed
          GetEventFreezeFrameDataEx
          GetEventStatus
          GetEventTested
          GetEventUdsStatus
          GetFaultDetectionCounter
          ResetEventDebounceStatus
          ResetEventStatus
          SetEventStatus
      DTC_EPBEepInitErrRR: required-interface=DiagnosticMonitor
        required-com-specs:
          GetDTCOfEvent
          GetEventExtendedDataRecordEx
          GetEventFailed
          GetEventFreezeFrameDataEx
          GetEventStatus
          GetEventTested
          GetEventUdsStatus
          GetFaultDetectionCounter
          ResetEventDebounceStatus
          ResetEventStatus
          SetEventStatus
      DTC_EPBFreeRunCurErrRL: required-interface=DiagnosticMonitor
        required-com-specs:
          GetDTCOfEvent
          GetEventExtendedDataRecordEx
          GetEventFailed
          GetEventFreezeFrameDataEx
          GetEventStatus
          GetEventTested
          GetEventUdsStatus
          GetFaultDetectionCounter
          ResetEventDebounceStatus
          ResetEventStatus
          SetEventStatus
      DTC_EPBFreeRunCurErrRR: required-interface=DiagnosticMonitor
        required-com-specs:
          GetDTCOfEvent
          GetEventExtendedDataRecordEx
          GetEventFailed
          GetEventFreezeFrameDataEx
          GetEventStatus
          GetEventTested
          GetEventUdsStatus
          GetFaultDetectionCounter
          ResetEventDebounceStatus
          ResetEventStatus
          SetEventStatus
      DTC_EPBHostHSPFaultRL: required-interface=DiagnosticMonitor
        required-com-specs:
          GetDTCOfEvent
          GetEventExtendedDataRecordEx
          GetEventFailed
          GetEventFreezeFrameDataEx
          GetEventStatus
          GetEventTested
          GetEventUdsStatus
          GetFaultDetectionCounter
          ResetEventDebounceStatus
          ResetEventStatus
          SetEventStatus
      DTC_EPBHostHSPFaultRR: required-interface=DiagnosticMonitor
        required-com-specs:
          GetDTCOfEvent
          GetEventExtendedDataRecordEx
          GetEventFailed
          GetEventFreezeFrameDataEx
          GetEventStatus
          GetEventTested
          GetEventUdsStatus
          GetFaultDetectionCounter
          ResetEventDebounceStatus
          ResetEventStatus
          SetEventStatus
      DTC_EPBHostNoActRL: required-interface=DiagnosticMonitor
        required-com-specs:
          GetDTCOfEvent
          GetEventExtendedDataRecordEx
          GetEventFailed
          GetEventFreezeFrameDataEx
          GetEventStatus
          GetEventTested
          GetEventUdsStatus
          GetFaultDetectionCounter
          ResetEventDebounceStatus
          ResetEventStatus
          SetEventStatus
      DTC_EPBHostNoActRR: required-interface=DiagnosticMonitor
        required-com-specs:
          GetDTCOfEvent
          GetEventExtendedDataRecordEx
          GetEventFailed
          GetEventFreezeFrameDataEx
          GetEventStatus
          GetEventTested
          GetEventUdsStatus
          GetFaultDetectionCounter
          ResetEventDebounceStatus
          ResetEventStatus
          SetEventStatus
      DTC_EPBIDCMsgInVld: required-interface=DiagnosticMonitor
        required-com-specs:
          GetDTCOfEvent
          GetEventExtendedDataRecordEx
          GetEventFailed
          GetEventFreezeFrameDataEx
          GetEventStatus
          GetEventTested
          GetEventUdsStatus
          GetFaultDetectionCounter
          ResetEventDebounceStatus
          ResetEventStatus
          SetEventStatus
      DTC_EPBLowVoltRL: required-interface=DiagnosticMonitor
        required-com-specs:
          GetDTCOfEvent
          GetEventExtendedDataRecordEx
          GetEventFailed
          GetEventFreezeFrameDataEx
          GetEventStatus
          GetEventTested
          GetEventUdsStatus
          GetFaultDetectionCounter
          ResetEventDebounceStatus
          ResetEventStatus
          SetEventStatus
      DTC_EPBLowVoltRR: required-interface=DiagnosticMonitor
        required-com-specs:
          GetDTCOfEvent
          GetEventExtendedDataRecordEx
          GetEventFailed
          GetEventFreezeFrameDataEx
          GetEventStatus
          GetEventTested
          GetEventUdsStatus
          GetFaultDetectionCounter
          ResetEventDebounceStatus
          ResetEventStatus
          SetEventStatus
      DTC_EPBMaintenanceRL: required-interface=DiagnosticMonitor
        required-com-specs:
          GetDTCOfEvent
          GetEventExtendedDataRecordEx
          GetEventFailed
          GetEventFreezeFrameDataEx
          GetEventStatus
          GetEventTested
          GetEventUdsStatus
          GetFaultDetectionCounter
          ResetEventDebounceStatus
          ResetEventStatus
          SetEventStatus
      DTC_EPBMaintenanceRR: required-interface=DiagnosticMonitor
        required-com-specs:
          GetDTCOfEvent
          GetEventExtendedDataRecordEx
          GetEventFailed
          GetEventFreezeFrameDataEx
          GetEventStatus
          GetEventTested
          GetEventUdsStatus
          GetFaultDetectionCounter
          ResetEventDebounceStatus
          ResetEventStatus
          SetEventStatus
      DTC_EPBMotCurFlutExcessRL: required-interface=DiagnosticMonitor
        required-com-specs:
          GetDTCOfEvent
          GetEventExtendedDataRecordEx
          GetEventFailed
          GetEventFreezeFrameDataEx
          GetEventStatus
          GetEventTested
          GetEventUdsStatus
          GetFaultDetectionCounter
          ResetEventDebounceStatus
          ResetEventStatus
          SetEventStatus
      DTC_EPBMotCurFlutExcessRR: required-interface=DiagnosticMonitor
        required-com-specs:
          GetDTCOfEvent
          GetEventExtendedDataRecordEx
          GetEventFailed
          GetEventFreezeFrameDataEx
          GetEventStatus
          GetEventTested
          GetEventUdsStatus
          GetFaultDetectionCounter
          ResetEventDebounceStatus
          ResetEventStatus
          SetEventStatus
      DTC_EPBOutOfSpecRL: required-interface=DiagnosticMonitor
        required-com-specs:
          GetDTCOfEvent
          GetEventExtendedDataRecordEx
          GetEventFailed
          GetEventFreezeFrameDataEx
          GetEventStatus
          GetEventTested
          GetEventUdsStatus
          GetFaultDetectionCounter
          ResetEventDebounceStatus
          ResetEventStatus
          SetEventStatus
      DTC_EPBOutOfSpecRR: required-interface=DiagnosticMonitor
        required-com-specs:
          GetDTCOfEvent
          GetEventExtendedDataRecordEx
          GetEventFailed
          GetEventFreezeFrameDataEx
          GetEventStatus
          GetEventTested
          GetEventUdsStatus
          GetFaultDetectionCounter
          ResetEventDebounceStatus
          ResetEventStatus
          SetEventStatus
      DTC_EPBOvrTempRL: required-interface=DiagnosticMonitor
        required-com-specs:
          GetDTCOfEvent
          GetEventExtendedDataRecordEx
          GetEventFailed
          GetEventFreezeFrameDataEx
          GetEventStatus
          GetEventTested
          GetEventUdsStatus
          GetFaultDetectionCounter
          ResetEventDebounceStatus
          ResetEventStatus
          SetEventStatus
      DTC_EPBOvrTempRR: required-interface=DiagnosticMonitor
        required-com-specs:
          GetDTCOfEvent
          GetEventExtendedDataRecordEx
          GetEventFailed
          GetEventFreezeFrameDataEx
          GetEventStatus
          GetEventTested
          GetEventUdsStatus
          GetFaultDetectionCounter
          ResetEventDebounceStatus
          ResetEventStatus
          SetEventStatus
      DTC_EPBOvrVoltRL: required-interface=DiagnosticMonitor
        required-com-specs:
          GetDTCOfEvent
          GetEventExtendedDataRecordEx
          GetEventFailed
          GetEventFreezeFrameDataEx
          GetEventStatus
          GetEventTested
          GetEventUdsStatus
          GetFaultDetectionCounter
          ResetEventDebounceStatus
          ResetEventStatus
          SetEventStatus
      DTC_EPBOvrVoltRR: required-interface=DiagnosticMonitor
        required-com-specs:
          GetDTCOfEvent
          GetEventExtendedDataRecordEx
          GetEventFailed
          GetEventFreezeFrameDataEx
          GetEventStatus
          GetEventTested
          GetEventUdsStatus
          GetFaultDetectionCounter
          ResetEventDebounceStatus
          ResetEventStatus
          SetEventStatus
      DTC_EPBPAAMsgChkErr: required-interface=DiagnosticMonitor
        required-com-specs:
          GetDTCOfEvent
          GetEventExtendedDataRecordEx
          GetEventFailed
          GetEventFreezeFrameDataEx
          GetEventStatus
          GetEventTested
          GetEventUdsStatus
          GetFaultDetectionCounter
          ResetEventDebounceStatus
          ResetEventStatus
          SetEventStatus
      DTC_EPBPAAMsgTimeOut: required-interface=DiagnosticMonitor
        required-com-specs:
          GetDTCOfEvent
          GetEventExtendedDataRecordEx
          GetEventFailed
          GetEventFreezeFrameDataEx
          GetEventStatus
          GetEventTested
          GetEventUdsStatus
          GetFaultDetectionCounter
          ResetEventDebounceStatus
          ResetEventStatus
          SetEventStatus
      DTC_EPBPosUnkownRL: required-interface=DiagnosticMonitor
        required-com-specs:
          GetDTCOfEvent
          GetEventExtendedDataRecordEx
          GetEventFailed
          GetEventFreezeFrameDataEx
          GetEventStatus
          GetEventTested
          GetEventUdsStatus
          GetFaultDetectionCounter
          ResetEventDebounceStatus
          ResetEventStatus
          SetEventStatus
      DTC_EPBPosUnkownRR: required-interface=DiagnosticMonitor
        required-com-specs:
          GetDTCOfEvent
          GetEventExtendedDataRecordEx
          GetEventFailed
          GetEventFreezeFrameDataEx
          GetEventStatus
          GetEventTested
          GetEventUdsStatus
          GetFaultDetectionCounter
          ResetEventDebounceStatus
          ResetEventStatus
          SetEventStatus
      DTC_EPBRBMMsgChkErr: required-interface=DiagnosticMonitor
        required-com-specs:
          GetDTCOfEvent
          GetEventExtendedDataRecordEx
          GetEventFailed
          GetEventFreezeFrameDataEx
          GetEventStatus
          GetEventTested
          GetEventUdsStatus
          GetFaultDetectionCounter
          ResetEventDebounceStatus
          ResetEventStatus
          SetEventStatus
      DTC_EPBRBMMsgInVld: required-interface=DiagnosticMonitor
        required-com-specs:
          GetDTCOfEvent
          GetEventExtendedDataRecordEx
          GetEventFailed
          GetEventFreezeFrameDataEx
          GetEventStatus
          GetEventTested
          GetEventUdsStatus
          GetFaultDetectionCounter
          ResetEventDebounceStatus
          ResetEventStatus
          SetEventStatus
      DTC_EPBRBMMsgTimeOut: required-interface=DiagnosticMonitor
        required-com-specs:
          GetDTCOfEvent
          GetEventExtendedDataRecordEx
          GetEventFailed
          GetEventFreezeFrameDataEx
          GetEventStatus
          GetEventTested
          GetEventUdsStatus
          GetFaultDetectionCounter
          ResetEventDebounceStatus
          ResetEventStatus
          SetEventStatus
      DTC_EPBRlsPwrLosRL: required-interface=DiagnosticMonitor
        required-com-specs:
          GetDTCOfEvent
          GetEventExtendedDataRecordEx
          GetEventFailed
          GetEventFreezeFrameDataEx
          GetEventStatus
          GetEventTested
          GetEventUdsStatus
          GetFaultDetectionCounter
          ResetEventDebounceStatus
          ResetEventStatus
          SetEventStatus
      DTC_EPBRollerBenchRL: required-interface=DiagnosticMonitor
        required-com-specs:
          GetDTCOfEvent
          GetEventExtendedDataRecordEx
          GetEventFailed
          GetEventFreezeFrameDataEx
          GetEventStatus
          GetEventTested
          GetEventUdsStatus
          GetFaultDetectionCounter
          ResetEventDebounceStatus
          ResetEventStatus
          SetEventStatus
      DTC_EPBRollerBenchRR: required-interface=DiagnosticMonitor
        required-com-specs:
          GetDTCOfEvent
          GetEventExtendedDataRecordEx
          GetEventFailed
          GetEventFreezeFrameDataEx
          GetEventStatus
          GetEventTested
          GetEventUdsStatus
          GetFaultDetectionCounter
          ResetEventDebounceStatus
          ResetEventStatus
          SetEventStatus
      DTC_EPBRRsPwRRosRR: required-interface=DiagnosticMonitor
        required-com-specs:
          GetDTCOfEvent
          GetEventExtendedDataRecordEx
          GetEventFailed
          GetEventFreezeFrameDataEx
          GetEventStatus
          GetEventTested
          GetEventUdsStatus
          GetFaultDetectionCounter
          ResetEventDebounceStatus
          ResetEventStatus
          SetEventStatus
      DTC_EPBSRSMsgChkErr: required-interface=DiagnosticMonitor
        required-com-specs:
          GetDTCOfEvent
          GetEventExtendedDataRecordEx
          GetEventFailed
          GetEventFreezeFrameDataEx
          GetEventStatus
          GetEventTested
          GetEventUdsStatus
          GetFaultDetectionCounter
          ResetEventDebounceStatus
          ResetEventStatus
          SetEventStatus
      DTC_EPBSRSMsgInVld: required-interface=DiagnosticMonitor
        required-com-specs:
          GetDTCOfEvent
          GetEventExtendedDataRecordEx
          GetEventFailed
          GetEventFreezeFrameDataEx
          GetEventStatus
          GetEventTested
          GetEventUdsStatus
          GetFaultDetectionCounter
          ResetEventDebounceStatus
          ResetEventStatus
          SetEventStatus
      DTC_EPBSRSMsgTimeOut: required-interface=DiagnosticMonitor
        required-com-specs:
          GetDTCOfEvent
          GetEventExtendedDataRecordEx
          GetEventFailed
          GetEventFreezeFrameDataEx
          GetEventStatus
          GetEventTested
          GetEventUdsStatus
          GetFaultDetectionCounter
          ResetEventDebounceStatus
          ResetEventStatus
          SetEventStatus
      DTC_EPBSwitchErr: required-interface=DiagnosticMonitor
        required-com-specs:
          GetDTCOfEvent
          GetEventExtendedDataRecordEx
          GetEventFailed
          GetEventFreezeFrameDataEx
          GetEventStatus
          GetEventTested
          GetEventUdsStatus
          GetFaultDetectionCounter
          ResetEventDebounceStatus
          ResetEventStatus
          SetEventStatus
      DTC_EPBSwitchStuckErr: required-interface=DiagnosticMonitor
        required-com-specs:
          GetDTCOfEvent
          GetEventExtendedDataRecordEx
          GetEventFailed
          GetEventFreezeFrameDataEx
          GetEventStatus
          GetEventTested
          GetEventUdsStatus
          GetFaultDetectionCounter
          ResetEventDebounceStatus
          ResetEventStatus
          SetEventStatus
      DTC_EPBUndrVoltRL: required-interface=DiagnosticMonitor
        required-com-specs:
          GetDTCOfEvent
          GetEventExtendedDataRecordEx
          GetEventFailed
          GetEventFreezeFrameDataEx
          GetEventStatus
          GetEventTested
          GetEventUdsStatus
          GetFaultDetectionCounter
          ResetEventDebounceStatus
          ResetEventStatus
          SetEventStatus
      DTC_EPBUndrVoltRR: required-interface=DiagnosticMonitor
        required-com-specs:
          GetDTCOfEvent
          GetEventExtendedDataRecordEx
          GetEventFailed
          GetEventFreezeFrameDataEx
          GetEventStatus
          GetEventTested
          GetEventUdsStatus
          GetFaultDetectionCounter
          ResetEventDebounceStatus
          ResetEventStatus
          SetEventStatus
      DTC_EPBUnecpectedPwrDwnRL: required-interface=DiagnosticMonitor
        required-com-specs:
          GetDTCOfEvent
          GetEventExtendedDataRecordEx
          GetEventFailed
          GetEventFreezeFrameDataEx
          GetEventStatus
          GetEventTested
          GetEventUdsStatus
          GetFaultDetectionCounter
          ResetEventDebounceStatus
          ResetEventStatus
          SetEventStatus
      DTC_EPBUnecpectedPwrDwnRR: required-interface=DiagnosticMonitor
        required-com-specs:
          GetDTCOfEvent
          GetEventExtendedDataRecordEx
          GetEventFailed
          GetEventFreezeFrameDataEx
          GetEventStatus
          GetEventTested
          GetEventUdsStatus
          GetFaultDetectionCounter
          ResetEventDebounceStatus
          ResetEventStatus
          SetEventStatus
      DTC_EPBVCUMsgChkErr: required-interface=DiagnosticMonitor
        required-com-specs:
          GetDTCOfEvent
          GetEventExtendedDataRecordEx
          GetEventFailed
          GetEventFreezeFrameDataEx
          GetEventStatus
          GetEventTested
          GetEventUdsStatus
          GetFaultDetectionCounter
          ResetEventDebounceStatus
          ResetEventStatus
          SetEventStatus
      DTC_EPBVCUMsgInVld: required-interface=DiagnosticMonitor
        required-com-specs:
          GetDTCOfEvent
          GetEventExtendedDataRecordEx
          GetEventFailed
          GetEventFreezeFrameDataEx
          GetEventStatus
          GetEventTested
          GetEventUdsStatus
          GetFaultDetectionCounter
          ResetEventDebounceStatus
          ResetEventStatus
          SetEventStatus
      DTC_EPBVCUMsgTimeOut: required-interface=DiagnosticMonitor
        required-com-specs:
          GetDTCOfEvent
          GetEventExtendedDataRecordEx
          GetEventFailed
          GetEventFreezeFrameDataEx
          GetEventStatus
          GetEventTested
          GetEventUdsStatus
          GetFaultDetectionCounter
          ResetEventDebounceStatus
          ResetEventStatus
          SetEventStatus
      DTC_EPBWrongPaprRL: required-interface=DiagnosticMonitor
        required-com-specs:
          GetDTCOfEvent
          GetEventExtendedDataRecordEx
          GetEventFailed
          GetEventFreezeFrameDataEx
          GetEventStatus
          GetEventTested
          GetEventUdsStatus
          GetFaultDetectionCounter
          ResetEventDebounceStatus
          ResetEventStatus
          SetEventStatus
      DTC_EPBWrongPaprRR: required-interface=DiagnosticMonitor
        required-com-specs:
          GetDTCOfEvent
          GetEventExtendedDataRecordEx
          GetEventFailed
          GetEventFreezeFrameDataEx
          GetEventStatus
          GetEventTested
          GetEventUdsStatus
          GetFaultDetectionCounter
          ResetEventDebounceStatus
          ResetEventStatus
          SetEventStatus
      DTC_EPBWrongVariantRL: required-interface=DiagnosticMonitor
        required-com-specs:
          GetDTCOfEvent
          GetEventExtendedDataRecordEx
          GetEventFailed
          GetEventFreezeFrameDataEx
          GetEventStatus
          GetEventTested
          GetEventUdsStatus
          GetFaultDetectionCounter
          ResetEventDebounceStatus
          ResetEventStatus
          SetEventStatus
      DTC_EPBWrongVariantRR: required-interface=DiagnosticMonitor
        required-com-specs:
          GetDTCOfEvent
          GetEventExtendedDataRecordEx
          GetEventFailed
          GetEventFreezeFrameDataEx
          GetEventStatus
          GetEventTested
          GetEventUdsStatus
          GetFaultDetectionCounter
          ResetEventDebounceStatus
          ResetEventStatus
          SetEventStatus
      DTC_EPBZCUFMsgChkErr: required-interface=DiagnosticMonitor
        required-com-specs:
          GetDTCOfEvent
          GetEventExtendedDataRecordEx
          GetEventFailed
          GetEventFreezeFrameDataEx
          GetEventStatus
          GetEventTested
          GetEventUdsStatus
          GetFaultDetectionCounter
          ResetEventDebounceStatus
          ResetEventStatus
          SetEventStatus
      DTC_EPBZCUFMsgInVld: required-interface=DiagnosticMonitor
        required-com-specs:
          GetDTCOfEvent
          GetEventExtendedDataRecordEx
          GetEventFailed
          GetEventFreezeFrameDataEx
          GetEventStatus
          GetEventTested
          GetEventUdsStatus
          GetFaultDetectionCounter
          ResetEventDebounceStatus
          ResetEventStatus
          SetEventStatus
      DTC_EPBZCUFMsgTimeOut: required-interface=DiagnosticMonitor
        required-com-specs:
          GetDTCOfEvent
          GetEventExtendedDataRecordEx
          GetEventFailed
          GetEventFreezeFrameDataEx
          GetEventStatus
          GetEventTested
          GetEventUdsStatus
          GetFaultDetectionCounter
          ResetEventDebounceStatus
          ResetEventStatus
          SetEventStatus
      DTC_EPBZCUTMsgChkErr: required-interface=DiagnosticMonitor
        required-com-specs:
          GetDTCOfEvent
          GetEventExtendedDataRecordEx
          GetEventFailed
          GetEventFreezeFrameDataEx
          GetEventStatus
          GetEventTested
          GetEventUdsStatus
          GetFaultDetectionCounter
          ResetEventDebounceStatus
          ResetEventStatus
          SetEventStatus
      DTC_EPBZCUTMsgInVld: required-interface=DiagnosticMonitor
        required-com-specs:
          GetDTCOfEvent
          GetEventExtendedDataRecordEx
          GetEventFailed
          GetEventFreezeFrameDataEx
          GetEventStatus
          GetEventTested
          GetEventUdsStatus
          GetFaultDetectionCounter
          ResetEventDebounceStatus
          ResetEventStatus
          SetEventStatus
      DTC_EPBZCUTMsgTimeOut: required-interface=DiagnosticMonitor
        required-com-specs:
          GetDTCOfEvent
          GetEventExtendedDataRecordEx
          GetEventFailed
          GetEventFreezeFrameDataEx
          GetEventStatus
          GetEventTested
          GetEventUdsStatus
          GetFaultDetectionCounter
          ResetEventDebounceStatus
          ResetEventStatus
          SetEventStatus
      EPB_cntPbcOutDiagActuationCounter: nonqueued-receiver-com-spec{data-element=EPB_cntPbcOutDiagActuationCounter/Val, filter=data-filter-type=ALWAYS, init-value=0}, required-interface=EPB_cntPbcOutDiagActuationCounter
      EPB_PbcOutPbcSoftwareVersion: nonqueued-receiver-com-spec{data-element=EPB_PbcOutPbcSoftwareVersion/Val, filter=data-filter-type=ALWAYS, init-value=6 x 0}, required-interface=EPB_PbcOutPbcSoftwareVersion
      EPB_SSMOutDataStorageWrite: nonqueued-receiver-com-spec{data-element=EPB_SSMOutDataStorageWrite/Val, filter=data-filter-type=ALWAYS, init-value=128 x 0}, required-interface=EPB_SSMOutDataStorageWrite
      EPB_stButtonOutFaultMonitorStatus: nonqueued-receiver-com-spec{data-element=EPB_stButtonOutFaultMonitorStatus/Val, filter=data-filter-type=ALWAYS, init-value=0}, required-interface=EPB_stButtonOutFaultMonitorStatus
      EPB_stPbcOutDiagActuatorState: nonqueued-receiver-com-spec{data-element=EPB_stPbcOutDiagActuatorState/Val, filter=data-filter-type=ALWAYS, init-value=0}, required-interface=EPB_stPbcOutDiagActuatorState
      EPB_stPbcOutEcuPowerLatchRequest: nonqueued-receiver-com-spec{data-element=EPB_stPbcOutEcuPowerLatchRequest/Val, filter=data-filter-type=ALWAYS, init-value=0}, required-interface=EPB_stPbcOutEcuPowerLatchRequest
      EPB_stPbcOutFaultStatus: nonqueued-receiver-com-spec{data-element=EPB_stPbcOutFaultStatus/Val, filter=data-filter-type=ALWAYS, init-value=40 x 0}, required-interface=EPB_stPbcOutFaultStatus
      EPB_stSsmOutCommunicationLatchRequest: nonqueued-receiver-com-spec{data-element=EPB_stSsmOutCommunicationLatchRequest/Val, filter=data-filter-type=ALWAYS, init-value=0}, required-interface=EPB_stSsmOutCommunicationLatchRequest
      EPB_stSsmOutEpbSwtCycle: nonqueued-receiver-com-spec{data-element=EPB_stSsmOutEpbSwtCycle/Val, filter=data-filter-type=ALWAYS, init-value=0}, required-interface=EPB_stSsmOutEpbSwtCycle
      EPB_stSsmOutFaultStatus: nonqueued-receiver-com-spec{data-element=EPB_stSsmOutFaultStatus/Val, filter=data-filter-type=ALWAYS, init-value=30 x 0}, required-interface=EPB_stSsmOutFaultStatus
      EPB_stSsmOutPrkBrkAplSwt: nonqueued-receiver-com-spec{data-element=EPB_stSsmOutPrkBrkAplSwt/Val, filter=data-filter-type=ALWAYS, init-value=0}, required-interface=EPB_stSsmOutPrkBrkAplSwt
      EPB_stSsmOutSysState: nonqueued-receiver-com-spec{data-element=EPB_stSsmOutSysState/Val, filter=data-filter-type=ALWAYS, init-value=0}, required-interface=EPB_stSsmOutSysState
      EPB_tPbcOutDiagBrakeTemperature: nonqueued-receiver-com-spec{data-element=EPB_tPbcOutDiagBrakeTemperature/Val, filter=data-filter-type=ALWAYS, init-value=0}, required-interface=EPB_tPbcOutDiagBrakeTemperature
      EPB_tqPbcOutDiagAchievedClampForce: nonqueued-receiver-com-spec{data-element=EPB_tqPbcOutDiagAchievedClampForce/Val, filter=data-filter-type=ALWAYS, init-value=0}, required-interface=EPB_tqPbcOutDiagAchievedClampForce
      EPBCalprDrvr_CurrMotDrvrCurr_a: nonqueued-receiver-com-spec{data-element=EPBCalprDrvr_CurrMotDrvrCurr_a/Val, filter=data-filter-type=ALWAYS, init-value=10 x 0}, required-interface=EPBCalprDrvr_CurrMotDrvrCurr_a
      gCFG_u8SsmInFunctionConfig: nonqueued-receiver-com-spec{data-element=gCFG_u8SsmInFunctionConfig/Val, filter=data-filter-type=ALWAYS, init-value=0}, required-interface=gCFG_u8SsmInFunctionConfig
      gCFG_u8SsmInVariantCoding: nonqueued-receiver-com-spec{data-element=gCFG_u8SsmInVariantCoding/Val, filter=data-filter-type=ALWAYS, init-value=[0, 0, 0, 0]}, required-interface=gCFG_u8SsmInVariantCoding
      gDiag_bDSMClear: nonqueued-receiver-com-spec{data-element=gDiag_bDSMClear/Val, filter=data-filter-type=ALWAYS, init-value=0}, required-interface=gDiag_bDSMClear
      gNVM_bSsminDataStorageValid: nonqueued-receiver-com-spec{data-element=gNVM_bSsminDataStorageValid/Val, filter=data-filter-type=ALWAYS, init-value=0}, required-interface=gNVM_bSsminDataStorageValid
      gNVM_u8SsminDataStorageRead_a: nonqueued-receiver-com-spec{data-element=gNVM_u8SsminDataStorageRead_a/Val, filter=data-filter-type=ALWAYS, init-value=128 x 0}, required-interface=gNVM_u8SsminDataStorageRead_a
    behavior EPB_SysSrvAdpCust_InternalBehavior: data-type-mapping=DTMS_EPB_SysSrvAdpCust
      init event EPB_SysSrvAdpCust_InitEvent: start-on-event=EPB_SysSrvAdpCust_Init
      timing event TMT_EPB_SysSrvAdpCust_Input_Runnable_10ms: start-on-event=EPB_SysSrvAdpCust_Input_Runnable_10ms, period=0.01
      init event EPB_SysSrvAdpCust_InPut_InitEvent: start-on-event=EPB_SysSrvAdpCust_Input_Runnable_Init
      timing event TMT_EPB_SysSrvAdpCust_Output_Runnable_10ms: start-on-event=EPB_SysSrvAdpCust_Output_Runnable_10ms, period=0.01
      init event EPB_SysSrvAdpCust_OutPut_InitEvent: start-on-event=EPB_SysSrvAdpCust_Output_Runnable_Init
      5 x runnable:
        EPB_SysSrvAdpCust_Init
        EPB_SysSrvAdpCust_Input_Runnable_10ms
          data-read-access:
            5 x access:
              IN_gDiag_bDSMClear_Val: accessed-variable=gDiag_bDSMClear.Val
              IN_gNVM_bSsminDataStorageValid_Val: accessed-variable=gNVM_bSsminDataStorageValid.Val
              IN_gNVM_u8SsminDataStorageRead_a_Val: accessed-variable=gNVM_u8SsminDataStorageRead_a.Val
              READ_gCFG_u8SsmInFunctionConfig_val: accessed-variable=gCFG_u8SsmInFunctionConfig.Val
              READ_gCFG_u8SsmInVariantCoding_Val: accessed-variable=gCFG_u8SsmInVariantCoding.Val
          data-write-access:
            8 x access:
              OUT_EPB_bFunctionFailed_Val: accessed-variable=EPB_bFunctionFailed.Val
              OUT_EPB_SSMInDataStorageRead_Val: accessed-variable=EPB_SSMInDataStorageRead.Val
              OUT_EPB_stButtonInFaultMonitorStatusReset_Val: accessed-variable=EPB_stButtonInFaultMonitorStatusReset.Val
              OUT_EPB_stSSMInDataStorageValid_Val: accessed-variable=EPB_stSSMInDataStorageValid.Val
              SEND_EPB_PbcInHostSwVersion_Val: accessed-variable=EPB_PbcInHostSwVersion.Val
              WRITE_EPB_stSsmInFunctionConfig_Val: accessed-variable=EPB_stSsmInFunctionConfig.Val
              WRITE_EPB_stSsmInVariantCode_Val: accessed-variable=EPB_stSsmInVariantCode.Val
              WRITE_EPB_stSsmInVehicleTypeCfg_Val: accessed-variable=EPB_stSsmInVehicleTypeCfg.Val
        EPB_SysSrvAdpCust_Input_Runnable_Init
          data-read-access:
            4 x access:
              IN_gNVM_bSsminDataStorageValid_Val: accessed-variable=gNVM_bSsminDataStorageValid.Val
              IN_gNVM_u8SsminDataStorageRead_a_Val: accessed-variable=gNVM_u8SsminDataStorageRead_a.Val
              READ_gCFG_u8SsmInFunctionConfig_val: accessed-variable=gCFG_u8SsmInFunctionConfig.Val
              READ_gCFG_u8SsmInVariantCoding_Val: accessed-variable=gCFG_u8SsmInVariantCoding.Val
          data-write-access:
            8 x access:
              OUT_EPB_bFunctionFailed_Val: accessed-variable=EPB_bFunctionFailed.Val
              OUT_EPB_SSMInDataStorageRead_Val: accessed-variable=EPB_SSMInDataStorageRead.Val
              OUT_EPB_stButtonInFaultMonitorStatusReset_Val: accessed-variable=EPB_stButtonInFaultMonitorStatusReset.Val
              OUT_EPB_stSSMInDataStorageValid_Val: accessed-variable=EPB_stSSMInDataStorageValid.Val
              SEND_EPB_PbcInHostSwVersion_Val: accessed-variable=EPB_PbcInHostSwVersion.Val
              WRITE_EPB_stSsmInFunctionConfig_Val: accessed-variable=EPB_stSsmInFunctionConfig.Val
              WRITE_EPB_stSsmInVariantCode_Val: accessed-variable=EPB_stSsmInVariantCode.Val
              WRITE_EPB_stSsmInVehicleTypeCfg_Val: accessed-variable=EPB_stSsmInVehicleTypeCfg.Val
        EPB_SysSrvAdpCust_Output_Runnable_10ms
          data-read-access:
            16 x access:
              IN_EPB_SSMOutDataStorageWrite_Val: accessed-variable=EPB_SSMOutDataStorageWrite.Val
              IN_gNVM_u8SsminDataStorageRead_a_Val: accessed-variable=gNVM_u8SsminDataStorageRead_a.Val
              READ_EPB_cntPbcOutDiagActuationCounter_Val: accessed-variable=EPB_cntPbcOutDiagActuationCounter.Val
              READ_EPB_stButtonOutFaultMonitorStatus_Val: accessed-variable=EPB_stButtonOutFaultMonitorStatus.Val
              READ_EPB_stPbcOutDiagActuatorState_Val: accessed-variable=EPB_stPbcOutDiagActuatorState.Val
              READ_EPB_stPbcOutEcuPowerLatchRequest_Val: accessed-variable=EPB_stPbcOutEcuPowerLatchRequest.Val
              READ_EPB_stPbcOutFaultStatus_Val: accessed-variable=EPB_stPbcOutFaultStatus.Val
              READ_EPB_stSsmOutCommunicationLatchRequest_Val: accessed-variable=EPB_stSsmOutCommunicationLatchRequest.Val
              READ_EPB_stSsmOutEpbSwtCycle_Val: accessed-variable=EPB_stSsmOutEpbSwtCycle.Val
              READ_EPB_stSsmOutFaultStatus_Val: accessed-variable=EPB_stSsmOutFaultStatus.Val
              READ_EPB_stSsmOutPrkBrkAplSwt_Val: accessed-variable=EPB_stSsmOutPrkBrkAplSwt.Val
              READ_EPB_stSsmOutSysState_Val: accessed-variable=EPB_stSsmOutSysState.Val
              READ_EPB_tPbcOutDiagBrakeTemperature_Val: accessed-variable=EPB_tPbcOutDiagBrakeTemperature.Val
              READ_EPB_tqPbcOutDiagAchievedClampForce_Val: accessed-variable=EPB_tqPbcOutDiagAchievedClampForce.Val
              READ_EPBCalprDrvr_CurrMotDrvrCurr_a_Val: accessed-variable=EPBCalprDrvr_CurrMotDrvrCurr_a.Val
              REC_EPB_PbcOutPbcSoftwareVersion_Val: accessed-variable=EPB_PbcOutPbcSoftwareVersion.Val
          data-write-access:
            15 x access:
              OUT_gEPB_u8SsmoutDataStorageWrite_a_Val: accessed-variable=gEPB_u8SsmoutDataStorageWrite_a.Val
              OUT_gEPB_u8SsmoutDataStorageWrtCnt_Val: accessed-variable=gEPB_u8SsmoutDataStorageWrtCnt.Val
              WRITE_gEPB_s16PbcOutCurrMotDrvrCurr_Val: accessed-variable=gEPB_s16PbcOutCurrMotDrvrCurr.Val
              WRITE_gEPB_s16PbcOutDiagBrakeTemperature_Val: accessed-variable=gEPB_s16PbcOutDiagBrakeTemperature.Val
              WRITE_gEPB_u16PbcOutDiagAchievedClampForce_Val: accessed-variable=gEPB_u16PbcOutDiagAchievedClampForce.Val
              WRITE_gEPB_u32AllowSleep_Local_Val: accessed-variable=gEPB_u32AllowSleep_Local.Val
              WRITE_gEPB_u32AllowSleep_NW_Val: accessed-variable=gEPB_u32AllowSleep_NW.Val
              WRITE_gEPB_u32PbcOutDiagActuationCounter_Val: accessed-variable=gEPB_u32PbcOutDiagActuationCounter.Val
              WRITE_gEPB_u8HostSoftwareVersion_Val: accessed-variable=gEPB_u8HostSoftwareVersion.Val
              WRITE_gEPB_u8PbcOutDiagActuatorState_Val: accessed-variable=gEPB_u8PbcOutDiagActuatorState.Val
              WRITE_gEPB_u8PbcOutPbcSoftwareVersion_Val: accessed-variable=gEPB_u8PbcOutPbcSoftwareVersion.Val
              WRITE_gEPB_u8SsmOutEpbSwtCycle_Val: accessed-variable=gEPB_u8SsmOutEpbSwtCycle.Val
              WRITE_gEPB_u8SsmOutPrkBrkAplSwt_Val: accessed-variable=gEPB_u8SsmOutPrkBrkAplSwt.Val
              WRITE_gEPB_u8SsmOutSysState_Val: accessed-variable=gEPB_u8SsmOutSysState.Val
              WRITE_gEPB_u8Wakeup_Val: accessed-variable=gEPB_u8Wakeup.Val
          79 x sync call, all with timeout=0.001:
            SC_DTC_EPBActDefecteErrRL_SetEventStatus: operation=DTC_EPBActDefecteErrRL.SetEventStatus
            SC_DTC_EPBActDefecteErrRR_SetEventStatus: operation=DTC_EPBActDefecteErrRR.SetEventStatus
            SC_DTC_EPBActOLRL_SetEventStatus: operation=DTC_EPBActOLRL.SetEventStatus
            SC_DTC_EPBActOLRR_SetEventStatus: operation=DTC_EPBActOLRR.SetEventStatus
            SC_DTC_EPBActStndstlRL_SetEventStatus: operation=DTC_EPBActStndstlRL.SetEventStatus
            SC_DTC_EPBActStndstlRR_SetEventStatus: operation=DTC_EPBActStndstlRR.SetEventStatus
            SC_DTC_EPBActuatorDmgRL_SetEventStatus: operation=DTC_EPBActuatorDmgRL.SetEventStatus
            SC_DTC_EPBActuatorDmgRR_SetEventStatus: operation=DTC_EPBActuatorDmgRR.SetEventStatus
            SC_DTC_EPBActuatorStukRL_SetEventStatus: operation=DTC_EPBActuatorStukRL.SetEventStatus
            SC_DTC_EPBActuatorStukRR_SetEventStatus: operation=DTC_EPBActuatorStukRR.SetEventStatus
            SC_DTC_EPBADBFRL_SetEventStatus: operation=DTC_EPBADBFRL.SetEventStatus
            SC_DTC_EPBADBFRR_SetEventStatus: operation=DTC_EPBADBFRR.SetEventStatus
            SC_DTC_EPBAplyPwrLosRL_SetEventStatus: operation=DTC_EPBAplyPwrLosRL.SetEventStatus
            SC_DTC_EPBAplyPwRRosRR_SetEventStatus: operation=DTC_EPBAplyPwRRosRR.SetEventStatus
            SC_DTC_EPBAssemblyTestRL_SetEventStatus: operation=DTC_EPBAssemblyTestRL.SetEventStatus
            SC_DTC_EPBAssemblyTestRR_SetEventStatus: operation=DTC_EPBAssemblyTestRR.SetEventStatus
            SC_DTC_EPBBCSMsgChkErr_SetEventStatus: operation=DTC_EPBBCSMsgChkErr.SetEventStatus
            SC_DTC_EPBBCSMsgInVld_SetEventStatus: operation=DTC_EPBBCSMsgInVld.SetEventStatus
            SC_DTC_EPBBCSMsgTimeOut_SetEventStatus: operation=DTC_EPBBCSMsgTimeOut.SetEventStatus
            SC_DTC_EPBCCUMsgInVld_SetEventStatus: operation=DTC_EPBCCUMsgInVld.SetEventStatus
            SC_DTC_EPBCCUMsgTimeOut_SetEventStatus: operation=DTC_EPBCCUMsgTimeOut.SetEventStatus
            SC_DTC_EPBClpFrcInsuffcientRL_SetEventStatus: operation=DTC_EPBClpFrcInsuffcientRL.SetEventStatus
            SC_DTC_EPBClpFrcInsuffcientRR_SetEventStatus: operation=DTC_EPBClpFrcInsuffcientRR.SetEventStatus
            SC_DTC_EPBDiagnosisModeRL_SetEventStatus: operation=DTC_EPBDiagnosisModeRL.SetEventStatus
            SC_DTC_EPBDiagnosisModeRR_SetEventStatus: operation=DTC_EPBDiagnosisModeRR.SetEventStatus
            SC_DTC_EPBEepInitErrRL_SetEventStatus: operation=DTC_EPBEepInitErrRL.SetEventStatus
            SC_DTC_EPBEepInitErrRR_SetEventStatus: operation=DTC_EPBEepInitErrRR.SetEventStatus
            SC_DTC_EPBFreeRunCurErrRL_SetEventStatus: operation=DTC_EPBFreeRunCurErrRL.SetEventStatus
            SC_DTC_EPBFreeRunCurErrRR_SetEventStatus: operation=DTC_EPBFreeRunCurErrRR.SetEventStatus
            SC_DTC_EPBHostHSPFaultRL_SetEventStatus: operation=DTC_EPBHostHSPFaultRL.SetEventStatus
            SC_DTC_EPBHostHSPFaultRR_SetEventStatus: operation=DTC_EPBHostHSPFaultRR.SetEventStatus
            SC_DTC_EPBHostNoActRL_SetEventStatus: operation=DTC_EPBHostNoActRL.SetEventStatus
            SC_DTC_EPBHostNoActRR_SetEventStatus: operation=DTC_EPBHostNoActRR.SetEventStatus
            SC_DTC_EPBIDCMsgInVld_SetEventStatus: operation=DTC_EPBIDCMsgInVld.SetEventStatus
            SC_DTC_EPBLowVoltRL_SetEventStatus: operation=DTC_EPBLowVoltRL.SetEventStatus
            SC_DTC_EPBLowVoltRR_SetEventStatus: operation=DTC_EPBLowVoltRR.SetEventStatus
            SC_DTC_EPBMaintenanceRL_SetEventStatus: operation=DTC_EPBMaintenanceRL.SetEventStatus
            SC_DTC_EPBMaintenanceRR_SetEventStatus: operation=DTC_EPBMaintenanceRR.SetEventStatus
            SC_DTC_EPBMotCurFlutExcessRL_SetEventStatus: operation=DTC_EPBMotCurFlutExcessRL.SetEventStatus
            SC_DTC_EPBMotCurFlutExcessRR_SetEventStatus: operation=DTC_EPBMotCurFlutExcessRR.SetEventStatus
            SC_DTC_EPBOutOfSpecRL_SetEventStatus: operation=DTC_EPBOutOfSpecRL.SetEventStatus
            SC_DTC_EPBOutOfSpecRR_SetEventStatus: operation=DTC_EPBOutOfSpecRR.SetEventStatus
            SC_DTC_EPBOvrTempRL_SetEventStatus: operation=DTC_EPBOvrTempRL.SetEventStatus
            SC_DTC_EPBOvrTempRR_SetEventStatus: operation=DTC_EPBOvrTempRR.SetEventStatus
            SC_DTC_EPBOvrVoltRL_SetEventStatus: operation=DTC_EPBOvrVoltRL.SetEventStatus
            SC_DTC_EPBOvrVoltRR_SetEventStatus: operation=DTC_EPBOvrVoltRR.SetEventStatus
            SC_DTC_EPBPAAMsgChkErr_SetEventStatus: operation=DTC_EPBPAAMsgChkErr.SetEventStatus
            SC_DTC_EPBPAAMsgTimeOut_SetEventStatus: operation=DTC_EPBPAAMsgTimeOut.SetEventStatus
            SC_DTC_EPBPosUnkownRL_SetEventStatus: operation=DTC_EPBPosUnkownRL.SetEventStatus
            SC_DTC_EPBPosUnkownRR_SetEventStatus: operation=DTC_EPBPosUnkownRR.SetEventStatus
            SC_DTC_EPBRBMMsgChkErr_SetEventStatus: operation=DTC_EPBRBMMsgChkErr.SetEventStatus
            SC_DTC_EPBRBMMsgInVld_SetEventStatus: operation=DTC_EPBRBMMsgInVld.SetEventStatus
            SC_DTC_EPBRBMMsgTimeOut_SetEventStatus: operation=DTC_EPBRBMMsgTimeOut.SetEventStatus
            SC_DTC_EPBRlsPwrLosRL_SetEventStatus: operation=DTC_EPBRlsPwrLosRL.SetEventStatus
            SC_DTC_EPBRollerBenchRL_SetEventStatus: operation=DTC_EPBRollerBenchRL.SetEventStatus
            SC_DTC_EPBRollerBenchRR_SetEventStatus: operation=DTC_EPBRollerBenchRR.SetEventStatus
            SC_DTC_EPBRRsPwRRosRR_SetEventStatus: operation=DTC_EPBRRsPwRRosRR.SetEventStatus
            SC_DTC_EPBSRSMsgChkErr_SetEventStatus: operation=DTC_EPBSRSMsgChkErr.SetEventStatus
            SC_DTC_EPBSRSMsgInVld_SetEventStatus: operation=DTC_EPBSRSMsgInVld.SetEventStatus
            SC_DTC_EPBSRSMsgTimeOut_SetEventStatus: operation=DTC_EPBSRSMsgTimeOut.SetEventStatus
            SC_DTC_EPBSwitchErr_SetEventStatus: operation=DTC_EPBSwitchErr.SetEventStatus
            SC_DTC_EPBSwitchStuckErr_SetEventStatus: operation=DTC_EPBSwitchStuckErr.SetEventStatus
            SC_DTC_EPBUndrVoltRL_SetEventStatus: operation=DTC_EPBUndrVoltRL.SetEventStatus
            SC_DTC_EPBUndrVoltRR_SetEventStatus: operation=DTC_EPBUndrVoltRR.SetEventStatus
            SC_DTC_EPBUnecpectedPwrDwnRL_SetEventStatus: operation=DTC_EPBUnecpectedPwrDwnRL.SetEventStatus
            SC_DTC_EPBUnecpectedPwrDwnRR_SetEventStatus: operation=DTC_EPBUnecpectedPwrDwnRR.SetEventStatus
            SC_DTC_EPBVCUMsgChkErr_SetEventStatus: operation=DTC_EPBVCUMsgChkErr.SetEventStatus
            SC_DTC_EPBVCUMsgInVld_SetEventStatus: operation=DTC_EPBVCUMsgInVld.SetEventStatus
            SC_DTC_EPBVCUMsgTimeOut_SetEventStatus: operation=DTC_EPBVCUMsgTimeOut.SetEventStatus
            SC_DTC_EPBWrongPaprRL_SetEventStatus: operation=DTC_EPBWrongPaprRL.SetEventStatus
            SC_DTC_EPBWrongPaprRR_SetEventStatus: operation=DTC_EPBWrongPaprRR.SetEventStatus
            SC_DTC_EPBWrongVariantRL_SetEventStatus: operation=DTC_EPBWrongVariantRL.SetEventStatus
            SC_DTC_EPBWrongVariantRR_SetEventStatus: operation=DTC_EPBWrongVariantRR.SetEventStatus
            SC_DTC_EPBZCUFMsgChkErr_SetEventStatus: operation=DTC_EPBZCUFMsgChkErr.SetEventStatus
            SC_DTC_EPBZCUFMsgInVld_SetEventStatus: operation=DTC_EPBZCUFMsgInVld.SetEventStatus
            SC_DTC_EPBZCUFMsgTimeOut_SetEventStatus: operation=DTC_EPBZCUFMsgTimeOut.SetEventStatus
            SC_DTC_EPBZCUTMsgChkErr_SetEventStatus: operation=DTC_EPBZCUTMsgChkErr.SetEventStatus
            SC_DTC_EPBZCUTMsgInVld_SetEventStatus: operation=DTC_EPBZCUTMsgInVld.SetEventStatus
            SC_DTC_EPBZCUTMsgTimeOut_SetEventStatus: operation=DTC_EPBZCUTMsgTimeOut.SetEventStatus
        EPB_SysSrvAdpCust_Output_Runnable_Init
          data-read-access:
            15 x access:
              IN_EPB_SSMOutDataStorageWrite_Val: accessed-variable=EPB_SSMOutDataStorageWrite.Val
              READ_EPB_cntPbcOutDiagActuationCounter_Val: accessed-variable=EPB_cntPbcOutDiagActuationCounter.Val
              READ_EPB_PbcOutPbcSoftwareVersion_Val: accessed-variable=EPB_PbcOutPbcSoftwareVersion.Val
              READ_EPB_stPbcOutDiagActuatorState_Val: accessed-variable=EPB_stPbcOutDiagActuatorState.Val
              READ_EPB_stPbcOutEcuPowerLatchRequest_Val: accessed-variable=EPB_stPbcOutEcuPowerLatchRequest.Val
              READ_EPB_stPbcOutFaultStatus_Val: accessed-variable=EPB_stPbcOutFaultStatus.Val
              READ_EPB_stSsmOutCommunicationLatchRequest_Val: accessed-variable=EPB_stSsmOutCommunicationLatchRequest.Val
              READ_EPB_stSsmOutFaultStatus_Val: accessed-variable=EPB_stSsmOutFaultStatus.Val
              READ_EPB_stSsmOutPrkBrkAplSwt_Val: accessed-variable=EPB_stSsmOutPrkBrkAplSwt.Val
              READ_EPB_stSsmOutSysState_Val: accessed-variable=EPB_stSsmOutSysState.Val
              READ_EPB_tPbcOutDiagBrakeTemperature_Val: accessed-variable=EPB_tPbcOutDiagBrakeTemperature.Val
              READ_EPB_tqPbcOutDiagAchievedClampForce_Val: accessed-variable=EPB_tqPbcOutDiagAchievedClampForce.Val
              READ_EPBCalprDrvr_CurrMotDrvrCurr_a_Val: accessed-variable=EPBCalprDrvr_CurrMotDrvrCurr_a.Val
              REC_EPB_stButtonOutFaultMonitorStatus_Val: accessed-variable=EPB_stButtonOutFaultMonitorStatus.Val
              REC_EPB_stSsmOutEpbSwtCycle_Val: accessed-variable=EPB_stSsmOutEpbSwtCycle.Val
          data-write-access:
            15 x access:
              OUT_gEPB_u8SsmoutDataStorageWrite_a_Val: accessed-variable=gEPB_u8SsmoutDataStorageWrite_a.Val
              OUT_gEPB_u8SsmoutDataStorageWrtCnt_Val: accessed-variable=gEPB_u8SsmoutDataStorageWrtCnt.Val
              READ_gEPB_u8SsmOutSysState_Val: accessed-variable=gEPB_u8SsmOutSysState.Val
              WRITE_gEPB_s16PbcOutCurrMotDrvrCurr_Val: accessed-variable=gEPB_s16PbcOutCurrMotDrvrCurr.Val
              WRITE_gEPB_s16PbcOutDiagBrakeTemperature_Val: accessed-variable=gEPB_s16PbcOutDiagBrakeTemperature.Val
              WRITE_gEPB_u16PbcOutDiagAchievedClampForce_Val: accessed-variable=gEPB_u16PbcOutDiagAchievedClampForce.Val
              WRITE_gEPB_u32AllowSleep_Local_Val: accessed-variable=gEPB_u32AllowSleep_Local.Val
              WRITE_gEPB_u32AllowSleep_NW_Val: accessed-variable=gEPB_u32AllowSleep_NW.Val
              WRITE_gEPB_u32PbcOutDiagActuationCounter_Val: accessed-variable=gEPB_u32PbcOutDiagActuationCounter.Val
              WRITE_gEPB_u8HostSoftwareVersion_Val: accessed-variable=gEPB_u8HostSoftwareVersion.Val
              WRITE_gEPB_u8PbcOutDiagActuatorState_Val: accessed-variable=gEPB_u8PbcOutDiagActuatorState.Val
              WRITE_gEPB_u8PbcOutPbcSoftwareVersion_Val: accessed-variable=gEPB_u8PbcOutPbcSoftwareVersion.Val
              WRITE_gEPB_u8SsmOutEpbSwtCycle_Val: accessed-variable=gEPB_u8SsmOutEpbSwtCycle.Val
              WRITE_gEPB_u8SsmOutPrkBrkAplSwt_Val: accessed-variable=gEPB_u8SsmOutPrkBrkAplSwt.Val
              WRITE_gEPB_u8Wakeup_Val: accessed-variable=gEPB_u8Wakeup.Val
  swc implementation EPB_SysSrvAdpCust_Implementation: behavior=EPB_SysSrvAdpCust_InternalBehavior
    code-descriptors:
      code Default: artifact-descriptors=autosar-engineering-object={short-label=Default, category=SWSRC}
package /UAES/ASW/Units
  unit A: display-name=A, factor-si-to-unit=1, offset-si-to-unit=0
  unit DegC: display-name=℃, factor-si-to-unit=1, offset-si-to-unit=0
  unit kN: display-name=kN, factor-si-to-unit=1, offset-si-to-unit=0
